VERSION ""

NS_ :

BS_:

BU_: Rover Jetson

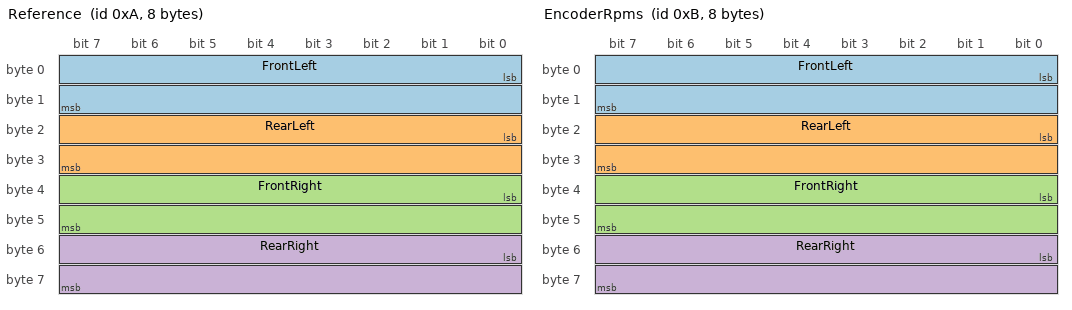
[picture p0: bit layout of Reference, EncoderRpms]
BO_ 10 Reference: 8 Jetson
	SG_ FrontLeft : 0|16@1- (1,0) [0|0] "rpm" Vector__XXX
	SG_ RearLeft : 16|16@1- (1,0) [0|0] "rpm" Vector__XXX
	SG_ FrontRight : 32|16@1- (1,0) [0|0] "rpm" Vector__XXX
	SG_ RearRight : 48|16@1- (1,0) [0|0] "rpm" Vector__XXX

BO_ 11 EncoderRpms: 8 Rover
	SG_ FrontLeft : 0|16@1- (1,0) [-180|180] "rpm" Vector__XXX
	SG_ RearLeft : 16|16@1- (1,0) [-180|180] "rpm" Vector__XXX
	SG_ FrontRight : 32|16@1- (1,0) [-180|180] "rpm" Vector__XXX
	SG_ RearRight : 48|16@1- (1,0) [-180|180] "rpm" Vector__XXX

CM_ BO_ 11 "Raw encoder RPMs. Physical RPM = raw_value * (1/182).";

BO_ 12 ImuGyroXy: 8 Rover
	SG_ GyroX : 0|32@1- (1,0) [0|0] "rad/s" Vector__XXX
	SG_ GyroY : 32|32@1- (1,0) [0|0] "rad/s" Vector__XXX

BO_ 13 ImuAccelXy: 8 Rover
	SG_ AccelX : 0|32@1- (1,0) [0|0] "m/s^2" Vector__XXX
	SG_ AccelY : 32|32@1- (1,0) [0|0] "m/s^2" Vector__XXX

BO_ 14 ImuZ: 8 Rover
	SG_ GyroZ : 0|32@1- (1,0) [0|0] "rad/s" Vector__XXX
	SG_ AccelZ : 32|32@1- (1,0) [0|0] "m/s^2" Vector__XXX

BA_DEF_ BO_  "VFrameFormat" ENUM  "StandardCAN","ExtendedCAN","reserved","J1939PG";
BA_DEF_  "DatabaseVersion" STRING ;
BA_DEF_  "BusType" STRING ;
BA_DEF_  "ProtocolType" STRING ;
BA_DEF_  "DatabaseCompiler" STRING ;
BA_DEF_DEF_  "VFrameFormat" "J1939PG";
BA_DEF_DEF_  "DatabaseVersion" "DEMO PLUS";
BA_DEF_DEF_  "BusType" "";
BA_DEF_DEF_  "ProtocolType" "";
BA_DEF_DEF_  "DatabaseCompiler" "";
BA_ "ProtocolType" "J1939";
BA_ "BusType" "CAN";
BA_ "DatabaseCompiler" "CSS ELECTRONICS (WWW.CSSELECTRONICS.COM)";
BA_ "DatabaseVersion" "1.0.0";
